# MSP430FR5962 register map
File version: 2.1
CPU: MSP430FR5962 r2p1, little endian, MPU, no FPU, 3 interrupt priority bits
Registers are 16-bit, read-write, reset 0x0 unless marked. A register's access mark holds for its fields unless they carry their own. Offsets are from the block's base; [hi:lo] are bit positions; {n}, {i} and the like mark numbered series; 'fields as' and 'values as' point back to an identical list.

## ADC12_B
Base 0x00000800
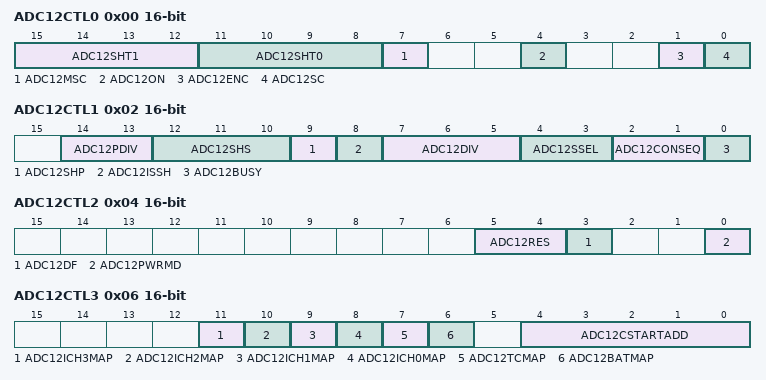
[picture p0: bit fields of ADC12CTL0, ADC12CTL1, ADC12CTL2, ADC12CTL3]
0x00 ADC12CTL0 — ADC12_B Control 0
  [15:12] ADC12SHT1 — [15:12] sample-and-hold time.
    0=4 ADC12CLK cycles; 1=8 ADC12CLK cycles; 2=16 ADC12CLK cycles; 3=32 ADC12CLK cycles; 4=64 ADC12CLK cycles; 5=96 ADC12CLK cycles; 6=128 ADC12CLK cycles; 7=192 ADC12CLK cycles; 8=256 ADC12CLK cycles; 9=384 ADC12CLK cycles; 10=512 ADC12CLK cycles
  [11:8] ADC12SHT0 — [11:8] sample-and-hold time.
    values as ADC12SHT1
  [7] ADC12MSC — [7:7] sample-and-hold time.
    0=The sampling timer requires a rising edge of the SHI signal to trigger each sample-and-convert; 1=The incidence of a positive(or for devices first rising edge of the) SHI signal triggers the sampling timer, but further sample-and-conversions are performed automatically as soon as the prior conversion is completed
  [4] ADC12ON — [4:4] ADC on
    0=ADC12_B off; 1=ADC12_B on
  [1] ADC12ENC — [1:1] enable conversion
    0=ADC12_B disabled; 1=ADC12_B enabled
  [0] ADC12SC — [0:0] start conversion
    0=No sample-and-conversion-start; 1=Start sample-and-conversion
0x02 ADC12CTL1 — ADC12_B Control 1
  [14:13] ADC12PDIV — [14:13] predivider
    0=Predivide by 1; 1=Predivide by 4; 2=Predivide by 32; 3=Predivide by 64
  [12:10] ADC12SHS — [12:10] sample-and-hold source select
    0=ADC12SC bit; {v}=see the device-specific data sheet for source (v=1..7)
  [9] ADC12SHP — [9:9] sample-and-hold pulse-mode select
    0=SAMPCON signal is sourced from the sample-input signal; 1=SAMPCON signal is sourced from the sampling timer
  [8] ADC12ISSH — [8:8] invert signal sample-and-hold
    0=The sample-input signal is not inverted; 1=The sample-input signal is inverted
  [7:5] ADC12DIV — [7:5] clock divider
    {v}=/{v+1} (v=0..7)
  [4:3] ADC12SSEL — [4:3] clock source select
    0=ADC12OSC (MODOSC); 1=ACLK; 2=MCLK; 3=SMCLK
  [2:1] ADC12CONSEQ — [2:1] conversion sequence mode select
    0=Single-channel, single-conversion; 1=Sequence-of-channels; 2=Repeat-single-channel; 3=Repeat-sequence-of-channels
  [0] ADC12BUSY — [0:0] ADC busy
    0=No operation is active; 1=A sequence, sample, or conversion is active
0x04 ADC12CTL2 — ADC12_B Control 2
  [5:4] ADC12RES — [5:4] resolution
    0=8BIT (8 bit (10 clock cycle conversion time)); 1=10BIT (10 bit (12 clock cycle conversion time)); 2=12BIT (12 bit (14 clock cycle conversion time))
  [3] ADC12DF — [3:3] data read-back format
    0=Binary unsigned. Theoretically for ADC12DIF = 0 and 12-bit mode the analog input voltage VREF results in 0000h, the analog input voltage + VREF results in 0FFFh.; 1=Signed binary (2s complement), left aligned. Theoretically, for ADC12DIF = 0 and 12-bit mode, the analog input voltage VREF results in 8000h, the analog input voltage + VREF results in 7FF0h.
  [0] ADC12PWRMD — [0:0] low-power mode
    0=Regular power mode where sample rate is not restricted; 1=Low power mode enable, ADC12CLK can not be greater than 1/4 the device-specific data sheet specified maximum for ADC12PWRMD = 0
0x06 ADC12CTL3 — ADC12_B Control 3
  [11] ADC12ICH3MAP — [11:11] int ch 3 sel to ADC in ch A26
    0=external pin is selected for ADC input channel A26; 1=ADC input channel internal 3 is selected for ADC input channel A26, see device-specific data sheet for availability
  [10] ADC12ICH2MAP — [10:10] int ch 2 sel to ADC in ch A27
    0=external pin is selected for ADC input channel A27; 1=ADC input channel internal 2 is selected for ADC input channel A27, see device-specific data sheet for availability
  [9] ADC12ICH1MAP — [9:9] int ch 1 sel to ADC in ch A28
    0=external pin is selected for ADC input channel A28; 1=ADC input channel internal 1 is selected for ADC input channel A28, see device-specific data sheet for availability
  [8] ADC12ICH0MAP — [8:8] int ch 0 sel to ADC in ch A29
    0=external pin is selected for ADC input channel A29; 1=ADC input channel internal 0 is selected for ADC input channel A29, see device-specific data sheet for availability
  [7] ADC12TCMAP — [7:7] temperature sensor ADC input channel selection
    0=external pin is selected for ADC input channel A30; 1=ADC internal temperature sensor channel is selected for ADC input channel A30
  [6] ADC12BATMAP — [6:6] 1/2 AVCC ADC input channel selection
    0=external pin is selected for ADC input channel A31; 1=ADC internal 1/2 x AVCC channel is selected for ADC input channel A31
  [4:0] ADC12CSTARTADD — [4:0] conversion start address
    {v}=ADC12MEM{v} (Conversion start address ADC12MEM{v}) (v=0..10); 11=ADC12MEM11 (Conversion start address ADC12MEM10); {v}=ADC12MEM{v} (Conversion start address ADC12MEM{v}) (v=12..31)
0x08 ADC12LO — ADC12_B Window Comparator Low Threshold Register
0x0A ADC12HI — ADC12_B Window Comparator High Threshold Register
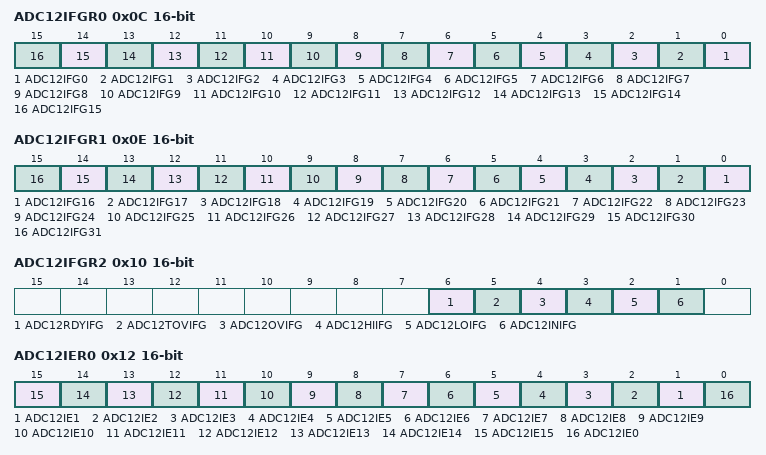
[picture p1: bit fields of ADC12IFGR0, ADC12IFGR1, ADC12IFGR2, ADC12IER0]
0x0C ADC12IFGR0 — ADC12_B Interrupt Flag 0
  [all] fields
    0=No interrupt pending; 1=Interrupt pending
  [n] ADC12IFG{n} (n=0..15) — [{n}:{n}] ADC12MEM{n} interrupt flag
0x0E ADC12IFGR1 — ADC12_B Interrupt Flag 1
  [all] fields
    0=No interrupt pending; 1=Interrupt pending
  [n-16] ADC12IFG{n} (n=16..31) — [{n-16}:{n-16}] ADC12MEM{n} interrupt flag
0x10 ADC12IFGR2 — ADC12_B Interrupt Flag 2
  [all] fields
    0=No interrupt pending; 1=Interrupt pending
  [6] ADC12RDYIFG — [6:6] reference buffer ready interrupt flag
  [5] ADC12TOVIFG — [5:5] conversion-time-overflow interrupt flag
  [4] ADC12OVIFG — [4:4] ADC12MEMx overflow-interrupt flag.
  [3] ADC12HIIFG — [3:3] Interrupt flag for ADC12MEMx ADC12HI
  [2] ADC12LOIFG — [2:2] Interrupt flag for ADC12MEMx ADC12LO
  [1] ADC12INIFG — [1:1] Interrupt flag for ADC12MEMx between ADC12HI and ADC12LO
0x12 ADC12IER0 — ADC12_B Interrupt Enable 0
  [all] fields
    0=Interrupt disabled; 1=Interrupt enabled
  [n] ADC12IE{n} (n=1..15) — [{n}:{n}] interrupt enable {n}
  [0] ADC12IE0 — [0:0] Interrupt enable 0
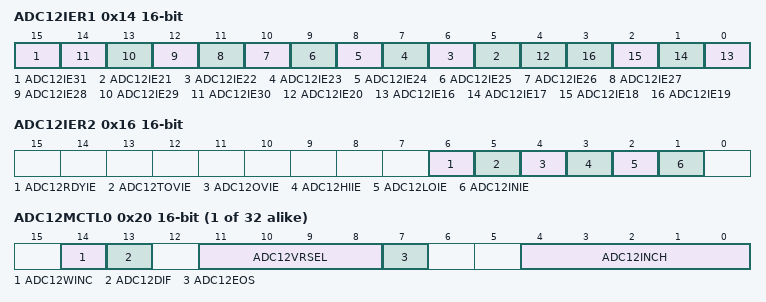
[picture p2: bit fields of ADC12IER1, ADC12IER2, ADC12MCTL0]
0x14 ADC12IER1 — ADC12_B Interrupt Enable 1
  [all] fields
    0=Interrupt disabled; 1=Interrupt enabled
  [15] ADC12IE31 — [15:15] interrupt enable 30
  [n-16] ADC12IE{n} (n=21..30) — [{n-16}:{n-16}] interrupt enable {n}
  [4] ADC12IE20 — [4:4] interrupt enable 19
  [n-16] ADC12IE{n} (n=16..19) — [{n-16}:{n-16}] interrupt enable {n}
0x16 ADC12IER2 — ADC12_B Interrupt Enable 2
  [all] fields
    0=Interrupt disabled; 1=Interrupt enabled
  [6] ADC12RDYIE — [6:6] interrupt enable ADC ref buffer ready
  [5] ADC12TOVIE — [5:5] conversion-time-overflow interrupt enable
  [4] ADC12OVIE — [4:4] ADC12MEMx overflow-interrupt enable
  [3] ADC12HIIE — [3:3] interrupt enable MEMx ADC12HI
  [2] ADC12LOIE — [2:2] interrupt enable MEMx ADC12LO
  [1] ADC12INIE — [1:1] interrupt enable MEMx between ADC12HI and LO
0x18 ADC12IV — ADC12_B Interrupt Vector
  [15:0] ADC12IV — [15:0] interrupt vector value
    0=NONE (Interrupt Source: No interrupt pending, Interrupt Flag: None); 2=ADC12OVIFG (Interrupt Source: ADC12MEMx overflow, Interrupt Flag: ADC12OVIFG, Interrupt Priority: Highest); 4=ADC12TOVIFG (Interrupt Source: Conversion time overflow, Interrupt Flag: ADC12TOVIFG); 6=ADC12HIIFG (Interrupt Source: ADC12 window high interrupt flag, Interrupt Flag: ADC12HIIFG); 8=ADC12LOIFG (Interrupt Source: ADC12 window low interrupt flag, Interrupt Flag: ADC12LOIFG); 10=ADC12INIFG (Interrupt Source: ADC12 in-window interrupt flag, Interrupt Flag: ADC12INIFG); 12=ADC12IFG0 (Interrupt Source: ADC12MEM0 interrupt flag, Interrupt Flag: ADC12IFG0); 14=ADC12IFG1 (Interrupt Source: ADC12MEM1 interrupt flag, Interrupt Flag: ADC12IFG1); 16=ADC12IFG2 (Interrupt Source: ADC12MEM2 interrupt flag, Interrupt Flag: ADC12IFG2); 18=ADC12IFG3 (Interrupt Source: ADC12MEM3 interrupt flag, Interrupt Flag: ADC12IFG3); 20=ADC12IFG4 (Interrupt Source: ADC12MEM4 interrupt flag, Interrupt Flag: ADC12IFG4); 22=ADC12IFG5 (Interrupt Source: ADC12MEM5 interrupt flag, Interrupt Flag: ADC12IFG5); 24=ADC12IFG6 (Interrupt Source: ADC12MEM6 interrupt flag, Interrupt Flag: ADC12IFG6); 26=ADC12IFG7 (Interrupt Source: ADC12MEM7 interrupt flag, Interrupt Flag: ADC12IFG7); 28=ADC12IFG8 (Interrupt Source: ADC12MEM8 interrupt flag, Interrupt Flag: ADC12IFG8); 30=ADC12IFG9 (Interrupt Source: ADC12MEM9 interrupt flag, Interrupt Flag: ADC12IFG9); 32=ADC12IFG10 (Interrupt Source: ADC12MEM10 interrupt flag, Interrupt Flag: ADC12IFG10); 34=ADC12IFG11 (Interrupt Source: ADC12MEM11 interrupt flag, Interrupt Flag: ADC12IFG11); 36=ADC12IFG12 (Interrupt Source: ADC12MEM12 interrupt flag, Interrupt Flag: ADC12IFG12); 38=ADC12IFG13 (Interrupt Source: ADC12MEM13 interrupt flag, Interrupt Flag: ADC12IFG13); 40=ADC12IFG14 (Interrupt Source: ADC12MEM14 interrupt flag, Interrupt Flag: ADC12IFG14); 42=ADC12IFG15 (Interrupt Source: ADC12MEM15 interrupt flag, Interrupt Flag: ADC12IFG15); 44=ADC12IFG16 (Interrupt Source: ADC12MEM16 interrupt flag, Interrupt Flag: ADC12IFG16); 46=ADC12IFG17 (Interrupt Source: ADC12MEM17 interrupt flag, Interrupt Flag: ADC12IFG17); 48=ADC12IFG18 (Interrupt Source: ADC12MEM18 interrupt flag, Interrupt Flag: ADC12IFG18); 50=ADC12IFG19 (Interrupt Source: ADC12MEM19 interrupt flag, Interrupt Flag: ADC12IFG19); 52=ADC12IFG20 (Interrupt Source: ADC12MEM20 interrupt flag, Interrupt Flag: ADC12IFG20); 54=ADC12IFG21 (Interrupt Source: ADC12MEM21 interrupt flag, Interrupt Flag: ADC12IFG21); 56=ADC12IFG22 (Interrupt Source: ADC12MEM22 interrupt flag, Interrupt Flag: ADC12IFG22); 58=ADC12IFG23 (Interrupt Source: ADC12MEM23 interrupt flag, Interrupt Flag: ADC12IFG23); 60=ADC12IFG24 (Interrupt Source: ADC12MEM24 interrupt flag, Interrupt Flag: ADC12IFG24); 62=ADC12IFG25 (Interrupt Source: ADC12MEM25 interrupt flag, Interrupt Flag: ADC12IFG25); 64=ADC12IFG26 (Interrupt Source: ADC12MEM26 interrupt flag, Interrupt Flag: ADC12IFG26); 66=ADC12IFG27 (Interrupt Source: ADC12MEM27 interrupt flag, Interrupt Flag: ADC12IFG27); 68=ADC12IFG28 (Interrupt Source: ADC12MEM28 interrupt flag, Interrupt Flag: ADC12IFG28); 70=ADC12IFG29 (Interrupt Source: ADC12MEM29 interrupt flag, Interrupt Flag: ADC12IFG29); 72=ADC12IFG30 (Interrupt Source: ADC12MEM30 interrupt flag, Interrupt Flag: ADC12IFG30); 74=ADC12IFG31 (Interrupt Source: ADC12MEM31 interrupt flag, Interrupt Flag: ADC12IFG31); 76=ADC12RDYIFG (Interrupt Source: ADC12RDYIFG interrupt flag, Interrupt Flag: ADC12RDYIFG)
{0x20+2i} ADC12MCTL{i} (i=0..31) — ADC12_B Memory Control 0 Register to ADC12_B Memory Control 31 Register
  [14] ADC12WINC — [14:14] Comparator window enable
    0=Comparator window disabled; 1=Comparator window enabled
  [13] ADC12DIF — [13:13] Differential mode.
    0=Single-ended mode enabled; 1=Differential mode enabled
  [11:8] ADC12VRSEL — [11:8] reference selection
    0=VR+ = AVCC, VR- = AVSS; 1=VR+ = VREF buffered, VR- = AVSS; 2=VR+ = VeREF-, VR- = AVSS; 3=VR+ = VeREF+ buffered, VR- = AVSS; 4=VR+ = VeREF+, VR- = AVSS; 5=VR+ = AVCC, VR- = VeREF+ buffered; 6=VR+ = AVCC, VR- = VeREF+; 7=VR+ = VREF buffered, VR- = VeREF+; 9=VR+ = AVCC, VR- = VREF buffered; 11=VR+ = VeREF+, VR- = VREF buffered; 12=VR+ = AVCC, VR- = VeREF-; 13=VR+ = VREF buffered, VR- = VeREF-; 14=VR+ = VeREF+, VR- = VeREF-; 15=VR+ = VeREF+ buffered, VR- = VeREF-
  [7] ADC12EOS — [7:7] End of sequence
    0=Not end of sequence; 1=End of sequence
  [4:0] ADC12INCH — [4:0] Input channel select
    0=If ADC12DIF = 0: A0; If ADC12DIF = 1: Ain+ = A0, Ain- = A1; 1=If ADC12DIF = 0: A1; If ADC12DIF = 1: Ain+ = A0, Ain- = A1; 2=If ADC12DIF = 0: A2; If ADC12DIF = 1: Ain+ = A2, Ain- = A3; 3=If ADC12DIF = 0: A3; If ADC12DIF = 1: Ain+ = A2, Ain- = A3; 4=If ADC12DIF = 0: A4; If ADC12DIF = 1: Ain+ = A4, Ain- = A5; 5=If ADC12DIF = 0: A5; If ADC12DIF = 1: Ain+ = A4, Ain- = A5; 6=If ADC12DIF = 0: A6; If ADC12DIF = 1: Ain+ = A6, Ain- = A7; 7=If ADC12DIF = 0: A7; If ADC12DIF = 1: Ain+ = A6, Ain- = A7; 8=If ADC12DIF = 0: A8; If ADC12DIF = 1: Ain+ = A8, Ain- = A9; 9=If ADC12DIF = 0: A9; If ADC12DIF = 1: Ain+ = A8, Ain- = A9; 10=If ADC12DIF = 0: A10; If ADC12DIF = 1: Ain+ = A10, Ain- = A11; 11=If ADC12DIF = 0: A11; If ADC12DIF = 1: Ain+ = A10, Ain- = A11; 12=If ADC12DIF = 0: A12; If ADC12DIF = 1: Ain+ = A12, Ain- = A13; 13=If ADC12DIF = 0: A13; If ADC12DIF = 1: Ain+ = A12, Ain- = A13; 14=If ADC12DIF = 0: A14; If ADC12DIF = 1: Ain+ = A14, Ain- = A15; 15=If ADC12DIF = 0: A15; If ADC12DIF = 1: Ain+ = A14, Ain- = A15; 16=If ADC12DIF = 0: A16; If ADC12DIF = 1: Ain+ = A16, Ain- = A17; 17=If ADC12DIF = 0: A17; If ADC12DIF = 1: Ain+ = A16, Ain- = A17; 18=If ADC12DIF = 0: A18; If ADC12DIF = 1: Ain+ = A18, Ain- = A19; 19=If ADC12DIF = 0: A19; If ADC12DIF = 1: Ain+ = A18, Ain- = A19; 20=If ADC12DIF = 0: A20; If ADC12DIF = 1: Ain+ = A20, Ain- = A21; 21=If ADC12DIF = 0: A21; If ADC12DIF = 1: Ain+ = A20, Ain- = A21; 22=If ADC12DIF = 0: A22; If ADC12DIF = 1: Ain+ = A22, Ain- = A23; 23=If ADC12DIF = 0: A23; If ADC12DIF = 1: Ain+ = A22, Ain- = A23; 24=If ADC12DIF = 0: A24; If ADC12DIF = 1: Ain+ = A24, Ain- = A25; 25=If ADC12DIF = 0: A25; If ADC12DIF = 1: Ain+ = A24, Ain- = A25; 26=If ADC12DIF = 0: A26; If ADC12DIF = 1: Ain+ = A26, Ain- =A27; 27=If ADC12DIF = 0: A27; If ADC12DIF = 1: Ain+ = A26, Ain- = A27; 28=If ADC12DIF = 0: A28; If ADC12DIF = 1: Ain+ = A28, Ain- = A29; 29=If ADC12DIF = 0: A29; If ADC12DIF = 1: Ain+ = A28, Ain- = A29; 30=If ADC12DIF = 0: A30; If ADC12DIF = 1: Ain+ = A30, Ain- = A31; 31=If ADC12DIF = 0: A31; If ADC12DIF = 1: Ain+ = A30, Ain- = A31
{0x60+2i} ADC12MEM{i} (i=0..31) — ADC12_B Memory 0 Register to ADC12_B Memory 31 Register
